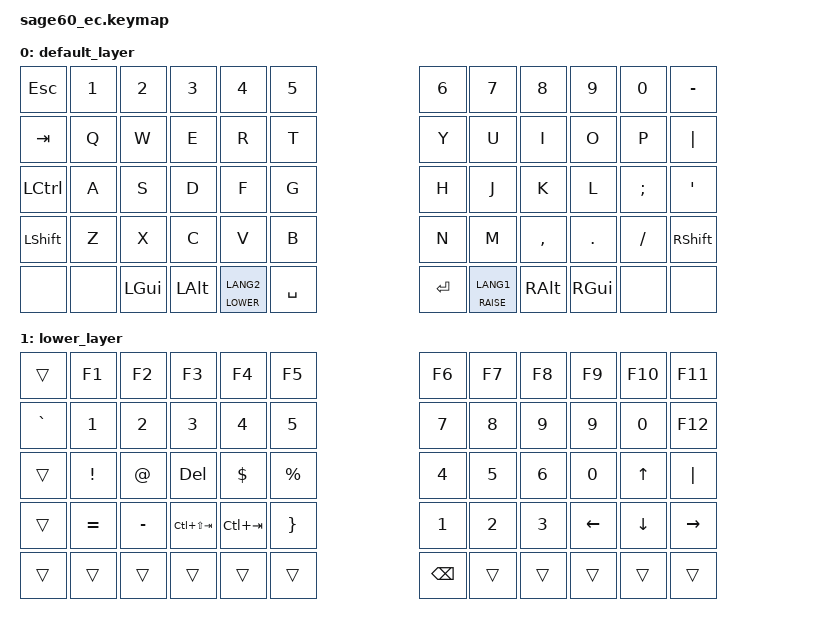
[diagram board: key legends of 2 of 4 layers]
/*
 * Copyright (c) 2020 The ZMK Contributors
 *
 * SPDX-License-Identifier: MIT
 */

#include <behaviors.dtsi>
#include <dt-bindings/zmk/keys.h>
#include <dt-bindings/zmk/outputs.h>
#include <dt-bindings/zmk/bt.h>

#define DEFAULT 0
#define LOWER   1
#define RAISE   2

&mt {
    tapping-term-ms = <400>;
};

/ {
    macros {
        password: password {
            label = "password";
            compatible = "zmk,behavior-macro";
            #binding-cells = <0>;
            wait-ms = <10>;
            tap-ms = <10>;
            bindings
                = <&macro_press &kp LSHFT>
                , <&macro_tap &kp A>
                ;
        };
    };
};

/ {

    conditional_layers {
        compatible = "zmk,conditional-layers";
        tri_layer {
            if-layers = <1 2>;
            then-layer = <3>;
        };
    };

    keymap {
        compatible = "zmk,keymap";

        default_layer {
// ------------------------------------------------------------------------------------------------------------
// |  `    |  1  |  2  |  3   |  4   |  5   |                   |  6   |  7    |  8    |  9   |   0   |       |
// |  ESC  |  Q  |  W  |  E   |  R   |  T   |                   |  Y   |  U    |  I    |  O   |   P   | BKSPC |
// |  TAB  |  A  |  S  |  D   |  F   |  G   |                   |  H   |  J    |  K    |  L   |   ;   |   '   |
// | SHIFT |  Z  |  X  |  C   |  V   |  B   |                   |  N   |  M    |  ,    |  .   |   /   | SHIFT |
//                     | GUI  | ALT  | LOWER|  SPACE |  | ENTER | RAISE| ALT   | GUI   |
            bindings = <
&kp ESC   &kp N1 &kp N2   &kp N3   &kp N4    &kp N5                      &kp N6 &kp N7    &kp N8    &kp N9   &kp N0   &kp MINUS
&kp TAB   &kp Q  &kp W    &kp E    &kp R     &kp T                       &kp Y  &kp U     &kp I     &kp O    &kp P    &kp PIPE
&kp LCTRL &kp A  &kp S    &kp D    &kp F     &kp G                       &kp H  &kp J     &kp K     &kp L    &kp SEMI &kp SQT
&kp LSHFT &kp Z  &kp X    &kp C    &kp V     &kp B                       &kp N  &kp M     &kp COMMA &kp DOT  &kp FSLH &kp RSHFT
&none     &none  &kp LGUI &kp LALT &lt LOWER LANG2 &kp SPACE  &kp ENTER &lt RAISE LANG1   &kp RALT  &kp RGUI  &none    &none
            >;

            sensor-bindings = <&inc_dec_kp C_VOL_UP C_VOL_DN &inc_dec_kp PG_UP PG_DN>;
        };

        lower_layer {
// TODO: Some binds are waiting for shifted keycode support.
// ------------------------------------------------------------------------------------------------------------
// |       |  F1 |  F2 |  F3  |  F4  |  F5  |                   |  F6  |  F7   |  F8   |  F9  |  F10  |  F11  |
// | `     |   1 |   2 |   3  |   4  |   5  |                   |   6  |   7   |   8   |   9  |    0  |  F12  |
// |       |  !  |  @  |  #   |  $   |  %   |                   |  ^   |  &    |  *    |  (   |   )   |   |   |
// |       |  =  |  -  |  +   |  {   |  }   |        |  |       |  [   |  ]    |  ;    |  :   |   \   |       |
//               |     |      |      |      |        |  |       |      |       |       |      |
            bindings = <
&trans    &kp F1    &kp F2    &kp F3      &kp F4    &kp F5                    &kp F6  &kp F7  &kp F8    &kp F9    &kp F10   &kp F11
&kp GRAVE &kp N1    &kp N2    &kp N3      &kp N4    &kp N5                    &kp N7  &kp N8  &kp N9    &kp N9    &kp N0    &kp F12
&trans    &kp EXCL  &kp AT    &kp DEL     &kp DLLR  &kp PRCNT                 &kp N4  &kp N5  &kp N6    &kp N0  &kp UP    &kp PIPE
&trans    &kp EQUAL &kp MINUS &kp LC(LS(TAB)) &kp LC(TAB)  &kp RBRC                  &kp N1  &kp N2  &kp N3    &kp LEFT  &kp DOWN  &kp RIGHT
&trans &trans                 &trans      &trans    &trans    &trans   &kp BSPC &trans    &trans   &trans                     &trans &trans
            >;
            sensor-bindings = <&inc_dec_kp C_VOL_UP C_VOL_DN &inc_dec_kp PG_UP PG_DN>;
        };

        raise_layer {
// ------------------------------------------------------------------------------------------------------------
// |BTCLR| BT1  | BT2  |  BT3  |  BT4  |  BT5 |                |      |      |       |      |       |       |
// |     | INS  | PSCR | GUI   |       |      |                | PGUP |      |   ^   |      |       |       |
// |     | ALT  | CTRL | SHIFT |       | CAPS |                | PGDN |   <- |   v   |  ->  |  DEL  | BKSPC |
// |     | UNDO | CUT  | COPY  | PASTE |      |      |  |      |      |      |       |      |       |       |
//              |      |       |       |      |      |  |      |      |      |       |      |
            bindings = <
&kp GRAVE &bt BT_SEL 0 &bt BT_SEL 1 &bt BT_SEL 2 &bt BT_SEL 3 &bt BT_SEL 4              &trans    &trans    &trans    &trans    &trans    &kp EQUAL
&bt BT_CLR &kp EXCL     &kp AT       &kp HASH     &kp DLLR     &kp PRCNT                &kp CARET &kp AMPS  &kp LPAR  &kp RPAR  &kp ASTRK &kp BSLH
&trans     &kp LALT     &kp LCTRL    &kp LSHFT    &trans       &kp CLCK                 &kp PG_DN &kp LEFT  &kp LBRC  &kp RBRC  &kp DOWN  &bt BT_CLR
&trans     &kp K_UNDO   &kp K_CUT    &kp K_COPY   &kp K_PASTE  &trans                   &trans    &trans    &kp LBKT  &kp RBKT  &trans    &trans
                        &trans       &trans       &trans       &trans  &trans   &trans  &trans    &trans    &trans    &trans
            >;

            sensor-bindings = <&inc_dec_kp C_VOL_UP C_VOL_DN &inc_dec_kp PG_UP PG_DN>;
        };

        tri_layer {
// ------------------------------------------------------------------------------------------------------------
// |BTCLR| BT1  | BT2  |  BT3  |  BT4  |  BT5 |                |      |      |       |      |       |       |
// |     | INS  | PSCR | GUI   |       |      |                | PGUP |      |   ^   |      |       |       |
// |     | ALT  | CTRL | SHIFT |       | CAPS |                | PGDN |   <- |   v   |  ->  |  DEL  | BKSPC |
// |     | UNDO | CUT  | COPY  | PASTE |      |      |  |      |      |      |       |      |       |       |
//              |      |       |       |      |      |  |      |      |      |       |      |
            bindings = <
&out OUT_TOG &bt BT_SEL 0 &bt BT_SEL 1 &bt BT_SEL 2 &bt BT_SEL 3 &bt BT_SEL 4              &bt BT_CLR   &trans    &trans    &trans    &trans    &password
&bt BT_CLR &kp EXCL     &kp AT       &kp HASH     &kp DLLR     &kp PRCNT                &kp CARET &kp AMPS  &kp ASTRK &kp LPAR  &kp RPAR  &kp EQUAL
&trans     &kp LALT     &kp LCTRL    &kp LSHFT    &trans       &kp CLCK                 &kp PG_DN &kp LEFT  &kp DOWN  &kp LBKT  &kp RBKT  &kp BSLH
&trans     &kp K_UNDO   &kp K_CUT    &kp K_COPY   &kp K_PASTE  &trans                   &trans    &trans    &trans    &kp LBRC  &kp RBRC  &trans
                        &trans       &trans       &trans       &trans  &trans   &trans  &trans    &trans    &trans    &trans
            >;

            sensor-bindings = <&inc_dec_kp C_VOL_UP C_VOL_DN &inc_dec_kp PG_UP PG_DN>;
        };
    };
};
